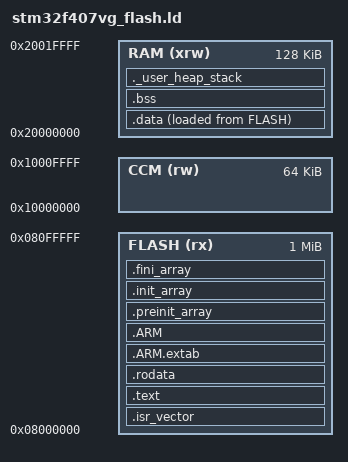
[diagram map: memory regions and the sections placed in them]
/*
 * GCC linker script for STM32F407VGH6 (RoboMaster C Board)
 * Memory layout extracted from official Keil project:
 *   IROM:  0x08000000 - 0x080FFFFF  (1 MB Flash)
 *   IRAM:  0x20000000 - 0x2001FFFF  (128 KB SRAM)
 *   IRAM2: 0x10000000 - 0x1000FFFF  (64 KB CCM, not used for heap)
 */

ENTRY(Reset_Handler)

_estack = 0x20020000;
_min_heap_size = 0x800;
_min_stack_size = 0x1000;

MEMORY
{
    FLASH (rx)      : ORIGIN = 0x08000000, LENGTH = 1024K
    RAM (xrw)       : ORIGIN = 0x20000000, LENGTH = 128K
    CCM (rw)        : ORIGIN = 0x10000000, LENGTH = 64K
}

SECTIONS
{
    .isr_vector :
    {
        . = ALIGN(4);
        KEEP(*(.isr_vector))
        . = ALIGN(4);
    } >FLASH

    .text :
    {
        . = ALIGN(4);
        *(.text)
        *(.text*)
        *(.glue_7)
        *(.glue_7t)
        *(.eh_frame)
        KEEP(*(.init))
        KEEP(*(.fini))
        . = ALIGN(4);
        _etext = .;
    } >FLASH

    .rodata :
    {
        . = ALIGN(4);
        *(.rodata)
        *(.rodata*)
        . = ALIGN(4);
    } >FLASH

    .ARM.extab :
    {
        *(.ARM.extab* .gnu.linkonce.armextab.*)
    } >FLASH

    .ARM :
    {
        __exidx_start = .;
        *(.ARM.exidx*)
        __exidx_end = .;
    } >FLASH

    .preinit_array :
    {
        PROVIDE_HIDDEN(__preinit_array_start = .);
        KEEP(*(.preinit_array*))
        PROVIDE_HIDDEN(__preinit_array_end = .);
    } >FLASH

    .init_array :
    {
        PROVIDE_HIDDEN(__init_array_start = .);
        KEEP(*(SORT(.init_array.*)))
        KEEP(*(.init_array*))
        PROVIDE_HIDDEN(__init_array_end = .);
    } >FLASH

    .fini_array :
    {
        PROVIDE_HIDDEN(__fini_array_start = .);
        KEEP(*(SORT(.fini_array.*)))
        KEEP(*(.fini_array*))
        PROVIDE_HIDDEN(__fini_array_end = .);
    } >FLASH

    _sidata = LOADADDR(.data);

    .data :
    {
        . = ALIGN(4);
        _sdata = .;
        *(.data)
        *(.data*)
        . = ALIGN(4);
        _edata = .;
    } >RAM AT> FLASH

    .bss :
    {
        . = ALIGN(4);
        _sbss = .;
        __bss_start__ = .;
        *(.bss)
        *(.bss*)
        *(COMMON)
        . = ALIGN(4);
        _ebss = .;
        __bss_end__ = .;
    } >RAM

    ._user_heap_stack :
    {
        . = ALIGN(8);
        PROVIDE ( end = . );
        PROVIDE ( _end = . );
        . = . + _min_heap_size;
        . = . + _min_stack_size;
        . = ALIGN(8);
    } >RAM


    .ARM.attributes 0 : { *(.ARM.attributes) }
}
